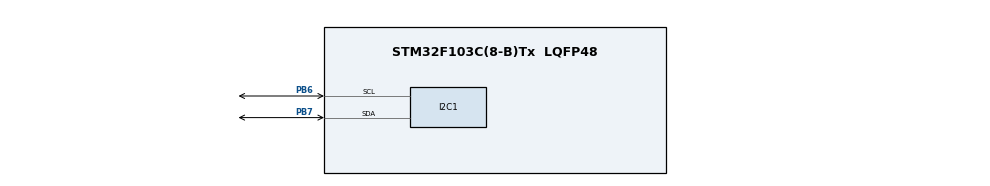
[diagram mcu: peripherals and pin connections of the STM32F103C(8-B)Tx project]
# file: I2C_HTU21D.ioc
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I2C1.I2C_Mode=I2C_Fast
Mcu.Family=STM32F1
Mcu.Name=STM32F103C(8-B)Tx
Mcu.Package=LQFP48
NVIC.I2C1_EV_IRQn=true\:0\:0\:false\:false\:true\:true\:true
NVIC.PriorityGroup=NVIC_PRIORITYGROUP_4
PA13.Mode=Serial_Wire
PA13.Signal=SYS_JTMS-SWDIO
PA14.Mode=Serial_Wire
PA14.Signal=SYS_JTCK-SWCLK
PB6.Mode=I2C
PB6.Signal=I2C1_SCL
PB7.Mode=I2C
PB7.Signal=I2C1_SDA
ProjectManager.HeapSize=0x200
ProjectManager.StackSize=0x400
ProjectManager.TargetToolchain=MDK-ARM V5.27
RCC.APB1Freq_Value=8000000
RCC.APB2Freq_Value=8000000
board=custom

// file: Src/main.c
/* USER CODE BEGIN Header */
/**
  ******************************************************************************
  * @file           : main.c
  * @brief          : Main program body
  ******************************************************************************
  * @attention
  *
  * <h2><center>&copy; Copyright (c) 2020 STMicroelectronics.
  * All rights reserved.</center></h2>
  *
  * This software component is licensed by ST under BSD 3-Clause license,
  * the "License"; You may not use this file except in compliance with the
  * License. You may obtain a copy of the License at:
  *                        opensource.org/licenses/BSD-3-Clause
  *
  ******************************************************************************
  */
/* USER CODE END Header */

#include "main.h"

I2C_HandleTypeDef hi2c1;

/* USER CODE BEGIN PV */

/* HTU21D variables */
uint8_t HTU21D_RX_Data[3];
float HTU21D_Temperature;
float HTU21D_Humidity;
uint16_t HTU21D_ADC_Raw;
uint8_t HTU21D_Temp_Cmd = 0xE3;
uint8_t HTU21D_Humi_Cmd = 0xE5;
#define HTU21D_Adress (0x40 << 1)

#define HTU21D_POLY 0x13100

/* USER CODE END PV */

void SystemClock_Config(void);
static void MX_GPIO_Init(void);
static void MX_I2C1_Init(void);

/* USER CODE BEGIN 0 */

	/* CRC Check */
uint8_t HTU21D_CRC8(uint16_t HTU21D_ADC, uint8_t *HTU21D_CRC)
{

	/* If ADC/CRC == 0 -> Sensor does not connected */
	if(HTU21D_ADC == 0 | *HTU21D_CRC == 0)
		return 0;

  for (uint8_t i = 0; i < 16; i++)
	{
		HTU21D_ADC = ((HTU21D_ADC & 0x8000) ? ((HTU21D_ADC << 1) ^ HTU21D_POLY) : (HTU21D_ADC <<= 1));
	}
  HTU21D_ADC >>= 8;

	if((uint8_t)HTU21D_ADC == *HTU21D_CRC)
		return 255; /* if OK */
	else
		return 0; /* if no OK */
}

/* USER CODE END 0 */

int main(void)
{

  /* MCU Configuration--------------------------------------------------------*/

  /* Reset of all peripherals, Initializes the Flash interface and the Systick. */
  HAL_Init();

  /* Configure the system clock */
  SystemClock_Config();

  /* Initialize all configured peripherals */
  MX_GPIO_Init();
  MX_I2C1_Init();

  /* Infinite loop */
/* USER CODE BEGIN WHILE */
while (1)
{
	/*******************************   HTU21D, I2C   **********************************/

	/* Temperature ---->; */
	HAL_I2C_Mem_Read_IT(&hi2c1, HTU21D_Adress, HTU21D_Temp_Cmd, I2C_MEMADD_SIZE_8BIT, HTU21D_RX_Data, 3);
	HTU21D_ADC_Raw = ((uint16_t)(HTU21D_RX_Data[0] << 8) | (HTU21D_RX_Data[1]));
	HTU21D_Temperature = (float)(HTU21D_ADC_Raw * 175.72 / 65536.00) - 46.85;
	HAL_Delay(100);

	/* Humidity ---->; */
	HAL_I2C_Mem_Read_IT(&hi2c1, HTU21D_Adress, HTU21D_Humi_Cmd, I2C_MEMADD_SIZE_8BIT, HTU21D_RX_Data, 3);
	HTU21D_ADC_Raw = ((uint16_t)(HTU21D_RX_Data[0] << 8) | (HTU21D_RX_Data[1]));
	HTU21D_Humidity = (float)(HTU21D_ADC_Raw * 125.0 / 65536.0) - 6.0;
	HAL_Delay(100);

	/******************************************************************************/

	/* USER CODE END WHILE */

  }
}

void SystemClock_Config(void)
{
  RCC_OscInitTypeDef RCC_OscInitStruct = {0};
  RCC_ClkInitTypeDef RCC_ClkInitStruct = {0};

  /** Initializes the CPU, AHB and APB busses clocks
  */
  RCC_OscInitStruct.OscillatorType = RCC_OSCILLATORTYPE_HSI;
  RCC_OscInitStruct.HSIState = RCC_HSI_ON;
  RCC_OscInitStruct.HSICalibrationValue = RCC_HSICALIBRATION_DEFAULT;
  RCC_OscInitStruct.PLL.PLLState = RCC_PLL_NONE;
  if (HAL_RCC_OscConfig(&RCC_OscInitStruct) != HAL_OK)
  {
    Error_Handler();
  }
  /** Initializes the CPU, AHB and APB busses clocks
  */
  RCC_ClkInitStruct.ClockType = RCC_CLOCKTYPE_HCLK|RCC_CLOCKTYPE_SYSCLK
                              |RCC_CLOCKTYPE_PCLK1|RCC_CLOCKTYPE_PCLK2;
  RCC_ClkInitStruct.SYSCLKSource = RCC_SYSCLKSOURCE_HSI;
  RCC_ClkInitStruct.AHBCLKDivider = RCC_SYSCLK_DIV1;
  RCC_ClkInitStruct.APB1CLKDivider = RCC_HCLK_DIV1;
  RCC_ClkInitStruct.APB2CLKDivider = RCC_HCLK_DIV1;

  if (HAL_RCC_ClockConfig(&RCC_ClkInitStruct, FLASH_LATENCY_0) != HAL_OK)
  {
    Error_Handler();
  }
}

static void MX_I2C1_Init(void)
{

  hi2c1.Instance = I2C1;
  hi2c1.Init.ClockSpeed = 400000;
  hi2c1.Init.DutyCycle = I2C_DUTYCYCLE_2;
  hi2c1.Init.OwnAddress1 = 0;
  hi2c1.Init.AddressingMode = I2C_ADDRESSINGMODE_7BIT;
  hi2c1.Init.DualAddressMode = I2C_DUALADDRESS_DISABLE;
  hi2c1.Init.OwnAddress2 = 0;
  hi2c1.Init.GeneralCallMode = I2C_GENERALCALL_DISABLE;
  hi2c1.Init.NoStretchMode = I2C_NOSTRETCH_DISABLE;
  if (HAL_I2C_Init(&hi2c1) != HAL_OK)
  {
    Error_Handler();
  }

}

static void MX_GPIO_Init(void)
{

  /* GPIO Ports Clock Enable */
  __HAL_RCC_GPIOA_CLK_ENABLE();
  __HAL_RCC_GPIOB_CLK_ENABLE();

}

void Error_Handler(void)
{
}

/************************ (C) COPYRIGHT STMicroelectronics *****END OF FILE****/
